# STM32F778 register map
File version: 1.7
CPU: CM7 r0p1, little endian, MPU, FPU, 4 interrupt priority bits
Registers are 32-bit, read-write, reset 0x0 unless marked. A register's access mark holds for its fields unless they carry their own. Offsets are from the block's base; [hi:lo] are bit positions; 'fields as' and 'values as' point back to an identical list.

## QUADSPI — QuadSPI interface
Base 0xA0001000
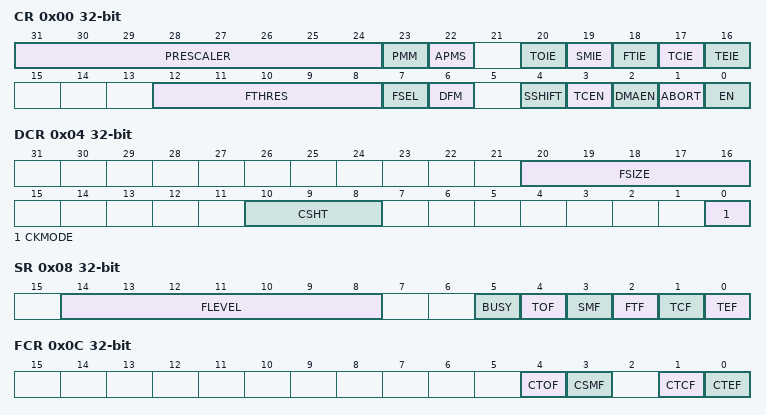
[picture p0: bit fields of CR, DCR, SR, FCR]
0x00 CR — control register
  [31:24] PRESCALER — Clock prescaler
  [23] PMM — Polling match mode
    0=AND match mode. SMF is set if all the unmasked bits received from the Flash memory match the corresponding bits in the match register.; 1=OR match mode. SMF is set if any one of the unmasked bits received from the Flash memory matches its corresponding bit in the match register.
  [22] APMS — Automatic poll mode stop
    0=NotStopOnMatch (Automatic polling mode is stopped only by abort or by disabling the QUADSPI.); 1=StopOnMatch (Automatic polling mode stops as soon as there is a match.)
  [20] TOIE — TimeOut interrupt enable
    0=Disabled (Interrupt disable); 1=Enabled (Interrupt enabled)
  [19] SMIE — Status match interrupt enable
    values as TOIE
  [18] FTIE — FIFO threshold interrupt enable
    values as TOIE
  [17] TCIE — Transfer complete interrupt enable
    values as TOIE
  [16] TEIE — Transfer error interrupt enable
    values as TOIE
  [12:8] FTHRES — IFO threshold level
  [7] FSEL — FLASH memory selection
    0=SelectFlash1 (FLASH 1 selected); 1=SelectFlash2 (FLASH 2 selected)
  [6] DFM — Dual-flash mode
    0=Disabled (Dual-flash mode disabled); 1=Enabled (Dual-flash mode enabled)
  [4] SSHIFT — Sample shift
    0=NoShift; 1=OneHalfCycleShift (1/2 cycle shift)
  [3] TCEN — Timeout counter enable
    0=Disabled (Timeout counter is disabled, and thus the chip select (nCS) remains active indefinitely after an access in memory-mapped mode.); 1=Enabled (Timeout counter is enabled, and thus the chip select is released in memory-mapped mode after TIMEOUT[15:0] cycles of Flash memory inactivity.)
  [2] DMAEN — DMA enable
    0=Disabled (DMA is disabled for indirect mode); 1=Enabled (DMA is enabled for indirect mode)
  [1] ABORT — Abort request
    0=NoAbortRequested; 1=AbortRequested
  [0] EN — Enable
    0=Disabled (QUADSPI is disabled); 1=Enabled (QUADSPI is enabled)
0x04 DCR — device configuration register
  [20:16] FSIZE — FLASH memory size
  [10:8] CSHT — Chip select high time
  [0] CKMODE — Mode 0 / mode 3
    0=Mode0 (CLK must stay low while nCS is high (chip select released). This is referred to as mode 0.); 1=Mode3 (CLK must stay high while nCS is high (chip select released). This is referred to as mode 3.)
0x08 SR ro — status register
  [14:8] FLEVEL range 0..31 — FIFO level
  [5] BUSY
    0=NotBusy; 1=Busy
  [4] TOF — Timeout flag
    0=NotTimeout; 1=Timeout
  [3] SMF — Status match flag
    0=NotMatched; 1=Matched
  [2] FTF — FIFO threshold flag
    0=NotReached; 1=Reached
  [1] TCF — Transfer complete flag
    0=NotComplete; 1=Complete
  [0] TEF — Transfer error flag
    0=NoError; 1=Error
0x0C FCR — flag clear register
  [4] CTOF — Clear timeout flag
    1=clears the TOF flag in the QUADSPI_SR register
  [3] CSMF — Clear status match flag
    1=clears the SMF flag in the QUADSPI_SR register
  [1] CTCF — Clear transfer complete flag
    1=clears the TCF flag in the QUADSPI_SR register
  [0] CTEF — Clear transfer error flag
    1=clears the TEF flag in the QUADSPI_SR register
0x10 DLR — data length register
  [31:0] DL — Data length
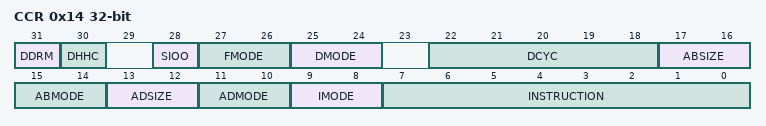
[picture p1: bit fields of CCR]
0x14 CCR — communication configuration register
  [31] DDRM — Double data rate mode
    0=Disabled (DDR Mode disabled); 1=Enabled (DDR Mode enabled)
  [30] DHHC — DDR hold half cycle
    0=NoDelay (Delay the data output using analog delay); 1=Delayed (Delay the data output by 1/4 of a QUADSPI output clock cycle.)
  [28] SIOO — Send instruction only once mode
    0=SendEveryTransaction (Send instruction on every transaction); 1=SendFirstCommand (Send instruction only for the first command)
  [27:26] FMODE — Functional mode
    0=Indirect write mode; 1=Indirect read mode; 2=Automatic polling mode; 3=Memory-mapped mode
  [25:24] DMODE — Data mode
    0=NoData; 1=SingleLine (Data on a single line); 2=TwoLines (Data on two lines); 3=FourLines (Data on four lines)
  [22:18] DCYC — Number of dummy cycles
  [17:16] ABSIZE — Alternate bytes size
    0=Bit8 (8-bit alternate byte); 1=Bit16 (16-bit alternate bytes); 2=Bit24 (24-bit alternate bytes); 3=Bit32 (32-bit alternate bytes)
  [15:14] ABMODE — Alternate bytes mode
    0=NoAlternateBytes; 1=SingleLine (Alternate bytes on a single line); 2=TwoLines (Alternate bytes on two lines); 3=FourLines (Alternate bytes on four lines)
  [13:12] ADSIZE — Address size
    0=Bit8 (8-bit address); 1=Bit16 (16-bit address); 2=Bit24 (24-bit address); 3=Bit32 (32-bit address)
  [11:10] ADMODE — Address mode
    0=NoAddress; 1=SingleLine (Address on a single line); 2=TwoLines (Address on two lines); 3=FourLines (Address on four lines)
  [9:8] IMODE — Instruction mode
    0=NoInstruction; 1=SingleLine (Instruction on a single line); 2=TwoLines (Instruction on two lines); 3=FourLines (Instruction on four lines)
  [7:0] INSTRUCTION
0x18 AR — address register
  [31:0] ADDRESS
0x1C ABR
  [31:0] ALTERNATE
0x20 DR — Data register: full word (32 bit) access
  [31:0] DATA
0x20 DR16 16-bit access not given (alternate view of DR) — Data register: half word (16 bit) access
  [15:0] DATA
0x20 DR8 8-bit access not given (alternate view of DR) — Data register: one byte (8 bit) access
  [7:0] DATA
0x24 PSMKR — polling status mask register
  [31:0] MASK — Status mask
0x28 PSMAR — polling status match register
  [31:0] MATCH — Status match
0x2C PIR — polling interval register
  [15:0] INTERVAL — Polling interval
0x30 LPTR — low-power timeout register
  [15:0] TIMEOUT — Timeout period
